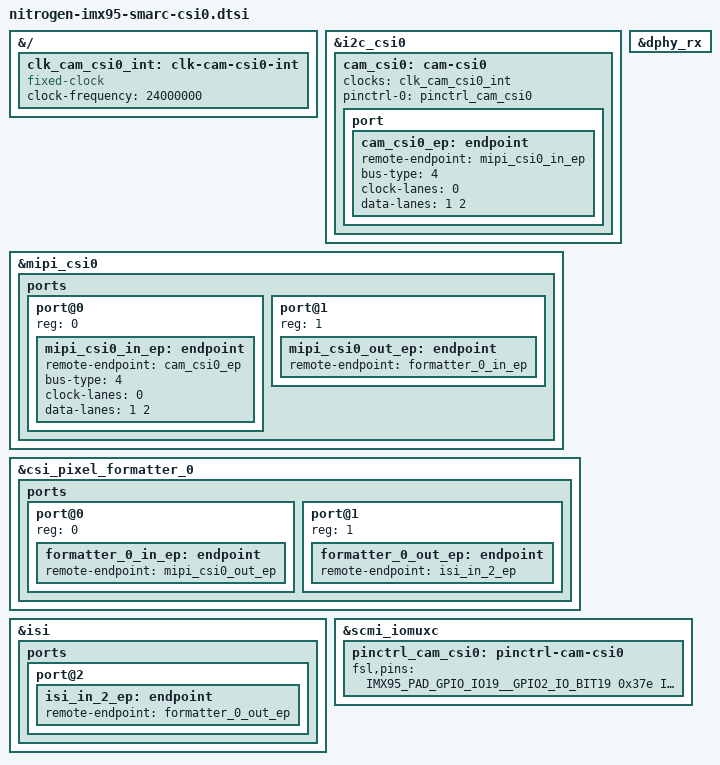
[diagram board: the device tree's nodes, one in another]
// SPDX-License-Identifier: (GPL-2.0+ OR MIT)
/*
 * Copyright 2025 Ezurio LLC
 */

#include <dt-bindings/gpio/gpio.h>
#include "imx95-pinfunc.h"

&{/} {
	clk_cam_csi0_int: clk-cam-csi0-int {
		compatible = "fixed-clock";
		#clock-cells = <0>;
		clock-frequency = <24000000>;
	};
};

&i2c_csi0 {
	#address-cells = <1>;
	#size-cells = <0>;

	cam_csi0: cam-csi0 {
		clocks = <&clk_cam_csi0_int>; /* On Camera module */
		clock-names = "xclk";

		pinctrl-names = "default";
		pinctrl-0 = <&pinctrl_cam_csi0>;

		port {
			cam_csi0_ep: endpoint {
				remote-endpoint = <&mipi_csi0_in_ep>;
				bus-type = <4>;
				clock-lanes = <0>;
				data-lanes = <1 2>;
			};
		};
	};
};

&mipi_csi0 {
	status = "okay";

	ports {
		#address-cells = <1>;
		#size-cells = <0>;

		port@0 {
			reg = <0>;

			mipi_csi0_in_ep: endpoint {
				remote-endpoint = <&cam_csi0_ep>;
				bus-type = <4>;
				clock-lanes = <0>;
				data-lanes = <1 2>;
			};
		};

		port@1 {
			reg = <1>;

			mipi_csi0_out_ep: endpoint {
				remote-endpoint = <&formatter_0_in_ep>;
			};
		};
	};
};

&csi_pixel_formatter_0 {
	status = "okay";

	ports {
		#address-cells = <1>;
		#size-cells = <0>;

		port@0 {
			reg = <0>;

			formatter_0_in_ep: endpoint {
				remote-endpoint = <&mipi_csi0_out_ep>;
			};
		};

		port@1 {
			reg = <1>;

			formatter_0_out_ep: endpoint {
				remote-endpoint = <&isi_in_2_ep>;
			};
		};
	};
};

&isi {
	status = "okay";

	ports {
		#address-cells = <1>;
		#size-cells = <0>;

		port@2 {
			isi_in_2_ep: endpoint {
				remote-endpoint = <&formatter_0_out_ep>;
			};
		};
	};
};

&dphy_rx {
	status = "okay";
};

&scmi_iomuxc {
	pinctrl_cam_csi0: pinctrl-cam-csi0 {
		fsl,pins = <
			IMX95_PAD_GPIO_IO19__GPIO2_IO_BIT19	0x37e
			IMX95_PAD_GPIO_IO23__GPIO2_IO_BIT23	0x37e
		>;
	};
};
